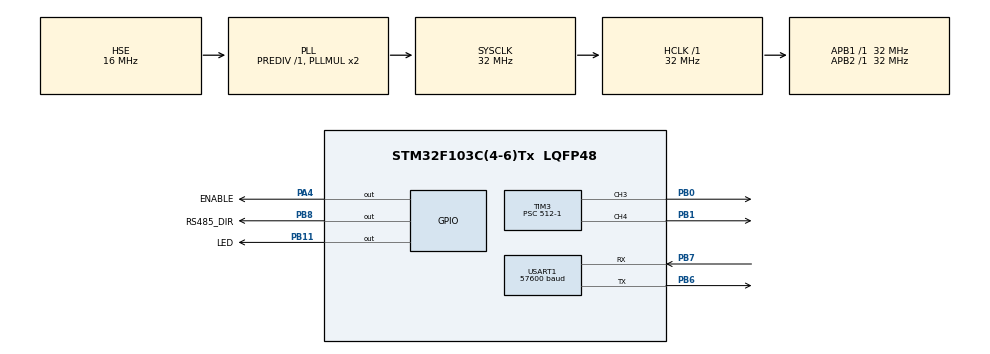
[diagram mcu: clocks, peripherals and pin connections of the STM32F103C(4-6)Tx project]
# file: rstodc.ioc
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Mcu.Family=STM32F1
Mcu.Name=STM32F103C(4-6)Tx
Mcu.Package=LQFP48
NVIC.PriorityGroup=NVIC_PRIORITYGROUP_4
NVIC.USART1_IRQn=true\:0\:0\:false\:false\:true\:true\:true\:true
PA13.Mode=Trace_Asynchronous_SW
PA13.Signal=SYS_JTMS-SWDIO
PA14.Mode=Trace_Asynchronous_SW
PA14.Signal=SYS_JTCK-SWCLK
PA4.GPIO_Label=ENABLE
PA4.PinState=GPIO_PIN_SET
PA4.Signal=GPIO_Output
PB0.Signal=S_TIM3_CH3
PB1.Signal=S_TIM3_CH4
PB11.GPIO_Label=LED
PB11.Signal=GPIO_Output
PB3.Mode=Trace_Asynchronous_SW
PB3.Signal=SYS_JTDO-TRACESWO
PB6.Mode=Asynchronous
PB6.Signal=USART1_TX
PB7.Mode=Asynchronous
PB7.Signal=USART1_RX
PB8.GPIO_Label=RS485_DIR
PB8.Signal=GPIO_Output
PD0-OSC_IN.Mode=HSE-External-Oscillator
PD0-OSC_IN.Signal=RCC_OSC_IN
PD1-OSC_OUT.Mode=HSE-External-Oscillator
PD1-OSC_OUT.Signal=RCC_OSC_OUT
ProjectManager.HeapSize=0x200
ProjectManager.StackSize=0x400
ProjectManager.TargetToolchain=STM32CubeIDE
RCC.AHBFreq_Value=32000000
RCC.APB1Freq_Value=32000000
RCC.APB1TimFreq_Value=32000000
RCC.APB2Freq_Value=32000000
RCC.APB2TimFreq_Value=32000000
RCC.HCLKFreq_Value=32000000
RCC.HSE_VALUE=16000000
RCC.PLLSourceVirtual=RCC_PLLSOURCE_HSE
RCC.SYSCLKFreq_VALUE=32000000
RCC.SYSCLKSource=RCC_SYSCLKSOURCE_PLLCLK
RCC.USBFreq_Value=32000000
SH.S_TIM3_CH3.0=TIM3_CH3,PWM Generation3 CH3
SH.S_TIM3_CH4.0=TIM3_CH4,PWM Generation4 CH4
TIM3.Channel-PWM\ Generation3\ CH3=TIM_CHANNEL_3
TIM3.Channel-PWM\ Generation4\ CH4=TIM_CHANNEL_4
TIM3.Period=127
TIM3.Prescaler=512-1
TIM3.Pulse-PWM\ Generation3\ CH3=0
USART1.BaudRate=57600
USART1.VirtualMode=VM_ASYNC
board=custom

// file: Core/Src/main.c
/* USER CODE BEGIN Header */
/**
  ******************************************************************************
  * @file           : main.c
  * @brief          : Main program body
  ******************************************************************************
  * @attention
  *
  * Copyright (c) 2022 STMicroelectronics.
  * All rights reserved.
  *
  * This software is licensed under terms that can be found in the LICENSE file
  * in the root directory of this software component.
  * If no LICENSE file comes with this software, it is provided AS-IS.
  *
  ******************************************************************************
  */
/* USER CODE END Header */
#include "main.h"

/* USER CODE BEGIN Includes */
#include "rstodc.h"
/* USER CODE END Includes */

 TIM_HandleTypeDef htim3;

UART_HandleTypeDef huart1;

void SystemClock_Config(void);
static void MX_GPIO_Init(void);
static void MX_TIM3_Init(void);
static void MX_USART1_UART_Init(void);

int main(void)
{

  /* MCU Configuration--------------------------------------------------------*/

  /* Reset of all peripherals, Initializes the Flash interface and the Systick. */
  HAL_Init();

  /* Configure the system clock */
  SystemClock_Config();

  /* Initialize all configured peripherals */
  MX_GPIO_Init();
  MX_TIM3_Init();
  MX_USART1_UART_Init();
  /* USER CODE BEGIN 2 */
  rstodc_init();
  /* USER CODE END 2 */

  /* Infinite loop */
  /* USER CODE BEGIN WHILE */
#pragma clang diagnostic push
#pragma ide diagnostic ignored "EndlessLoop"
  while (1)
  {
      rstodc_loop();
    /* USER CODE END WHILE */

    /* USER CODE BEGIN 3 */
  }
#pragma clang diagnostic pop
  /* USER CODE END 3 */
}

void SystemClock_Config(void)
{
  RCC_OscInitTypeDef RCC_OscInitStruct = {0};
  RCC_ClkInitTypeDef RCC_ClkInitStruct = {0};

  /** Initializes the RCC Oscillators according to the specified parameters
  * in the RCC_OscInitTypeDef structure.
  */
  RCC_OscInitStruct.OscillatorType = RCC_OSCILLATORTYPE_HSE;
  RCC_OscInitStruct.HSEState = RCC_HSE_ON;
  RCC_OscInitStruct.HSEPredivValue = RCC_HSE_PREDIV_DIV1;
  RCC_OscInitStruct.HSIState = RCC_HSI_ON;
  RCC_OscInitStruct.PLL.PLLState = RCC_PLL_ON;
  RCC_OscInitStruct.PLL.PLLSource = RCC_PLLSOURCE_HSE;
  RCC_OscInitStruct.PLL.PLLMUL = RCC_PLL_MUL2;
  if (HAL_RCC_OscConfig(&RCC_OscInitStruct) != HAL_OK)
  {
    Error_Handler();
  }

  /** Initializes the CPU, AHB and APB buses clocks
  */
  RCC_ClkInitStruct.ClockType = RCC_CLOCKTYPE_HCLK|RCC_CLOCKTYPE_SYSCLK
                              |RCC_CLOCKTYPE_PCLK1|RCC_CLOCKTYPE_PCLK2;
  RCC_ClkInitStruct.SYSCLKSource = RCC_SYSCLKSOURCE_PLLCLK;
  RCC_ClkInitStruct.AHBCLKDivider = RCC_SYSCLK_DIV1;
  RCC_ClkInitStruct.APB1CLKDivider = RCC_HCLK_DIV1;
  RCC_ClkInitStruct.APB2CLKDivider = RCC_HCLK_DIV1;

  if (HAL_RCC_ClockConfig(&RCC_ClkInitStruct, FLASH_LATENCY_1) != HAL_OK)
  {
    Error_Handler();
  }
}

static void MX_TIM3_Init(void)
{

  TIM_MasterConfigTypeDef sMasterConfig = {0};
  TIM_OC_InitTypeDef sConfigOC = {0};

  htim3.Instance = TIM3;
  htim3.Init.Prescaler = 512-1;
  htim3.Init.CounterMode = TIM_COUNTERMODE_UP;
  htim3.Init.Period = 127;
  htim3.Init.ClockDivision = TIM_CLOCKDIVISION_DIV1;
  htim3.Init.AutoReloadPreload = TIM_AUTORELOAD_PRELOAD_DISABLE;
  if (HAL_TIM_PWM_Init(&htim3) != HAL_OK)
  {
    Error_Handler();
  }
  sMasterConfig.MasterOutputTrigger = TIM_TRGO_RESET;
  sMasterConfig.MasterSlaveMode = TIM_MASTERSLAVEMODE_DISABLE;
  if (HAL_TIMEx_MasterConfigSynchronization(&htim3, &sMasterConfig) != HAL_OK)
  {
    Error_Handler();
  }
  sConfigOC.OCMode = TIM_OCMODE_PWM1;
  sConfigOC.Pulse = 0;
  sConfigOC.OCPolarity = TIM_OCPOLARITY_HIGH;
  sConfigOC.OCFastMode = TIM_OCFAST_DISABLE;
  if (HAL_TIM_PWM_ConfigChannel(&htim3, &sConfigOC, TIM_CHANNEL_3) != HAL_OK)
  {
    Error_Handler();
  }
  if (HAL_TIM_PWM_ConfigChannel(&htim3, &sConfigOC, TIM_CHANNEL_4) != HAL_OK)
  {
    Error_Handler();
  }
  HAL_TIM_MspPostInit(&htim3);

}

static void MX_USART1_UART_Init(void)
{

  huart1.Instance = USART1;
  huart1.Init.BaudRate = 57600;
  huart1.Init.WordLength = UART_WORDLENGTH_8B;
  huart1.Init.StopBits = UART_STOPBITS_1;
  huart1.Init.Parity = UART_PARITY_NONE;
  huart1.Init.Mode = UART_MODE_TX_RX;
  huart1.Init.HwFlowCtl = UART_HWCONTROL_NONE;
  huart1.Init.OverSampling = UART_OVERSAMPLING_16;
  if (HAL_UART_Init(&huart1) != HAL_OK)
  {
    Error_Handler();
  }

}

static void MX_GPIO_Init(void)
{
  GPIO_InitTypeDef GPIO_InitStruct = {0};

  /* GPIO Ports Clock Enable */
  __HAL_RCC_GPIOD_CLK_ENABLE();
  __HAL_RCC_GPIOA_CLK_ENABLE();
  __HAL_RCC_GPIOB_CLK_ENABLE();

  /*Configure GPIO pin Output Level */
  HAL_GPIO_WritePin(ENABLE_GPIO_Port, ENABLE_Pin, GPIO_PIN_SET);

  /*Configure GPIO pin Output Level */
  HAL_GPIO_WritePin(GPIOB, LED_Pin|RS485_DIR_Pin, GPIO_PIN_RESET);

  /*Configure GPIO pin : ENABLE_Pin */
  GPIO_InitStruct.Pin = ENABLE_Pin;
  GPIO_InitStruct.Mode = GPIO_MODE_OUTPUT_PP;
  GPIO_InitStruct.Pull = GPIO_NOPULL;
  GPIO_InitStruct.Speed = GPIO_SPEED_FREQ_LOW;
  HAL_GPIO_Init(ENABLE_GPIO_Port, &GPIO_InitStruct);

  /*Configure GPIO pins : LED_Pin RS485_DIR_Pin */
  GPIO_InitStruct.Pin = LED_Pin|RS485_DIR_Pin;
  GPIO_InitStruct.Mode = GPIO_MODE_OUTPUT_PP;
  GPIO_InitStruct.Pull = GPIO_NOPULL;
  GPIO_InitStruct.Speed = GPIO_SPEED_FREQ_LOW;
  HAL_GPIO_Init(GPIOB, &GPIO_InitStruct);

}

void Error_Handler(void)
{
  __disable_irq();
  while (1)
  {
  }
}
